VERSION ""

NS_ :

BS_:

BU_: EON XXX INTERCEPTOR ANY ACTUATOR SAFETY

CM_ "KommuActuator CAN messages starts here";

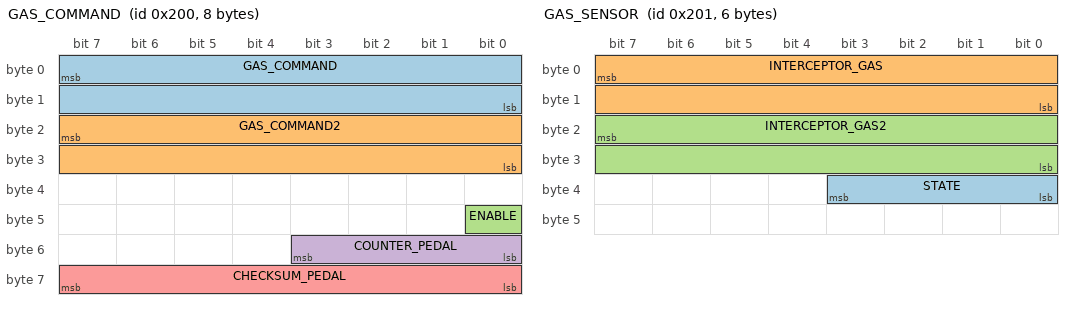
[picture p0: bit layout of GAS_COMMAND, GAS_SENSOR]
BO_ 512 GAS_COMMAND: 8 SAFETY
 SG_ GAS_COMMAND : 7|16@0+ (1,0) [0|1] "" ACTUATOR
 SG_ GAS_COMMAND2 : 23|16@0+ (1,0) [0|1] "" ACTUATOR
 SG_ ENABLE : 40|1@0+ (1,0) [0|1] "" ACTUATOR
 SG_ COUNTER_PEDAL : 51|4@0+ (1,0) [0|15] "" ACTUATOR
 SG_ CHECKSUM_PEDAL : 63|8@0+ (1,0) [0|255] "" ACTUATOR

BO_ 513 GAS_SENSOR: 6 ACTUATOR
 SG_ STATE : 35|4@0+ (1,0) [0|15] "" SAFETY
 SG_ INTERCEPTOR_GAS : 7|16@0+ (0.0007,-0.342) [0|1] "" SAFETY
 SG_ INTERCEPTOR_GAS2 : 23|16@0+ (0.0007,-0.691) [0|1] "" SAFETY

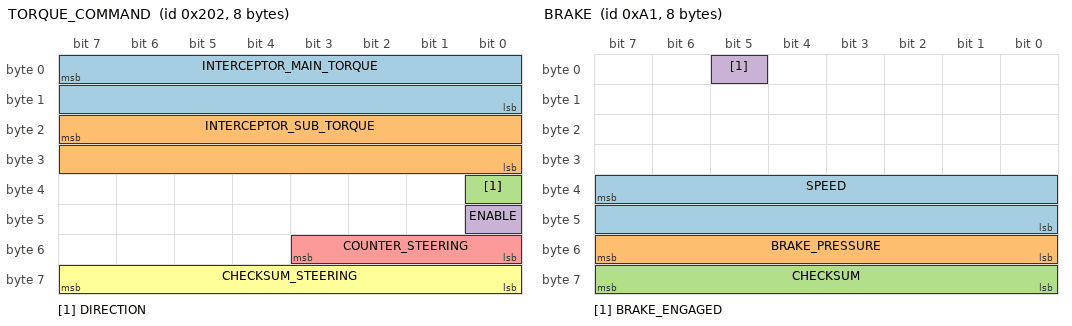
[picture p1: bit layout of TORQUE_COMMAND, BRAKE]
BO_ 514 TORQUE_COMMAND: 8 SAFETY
 SG_ INTERCEPTOR_MAIN_TORQUE : 7|16@0+ (1,0) [0|1] "" ACTUATOR
 SG_ INTERCEPTOR_SUB_TORQUE : 23|16@0+ (1,0) [0|1] "" ACTUATOR
 SG_ DIRECTION : 32|1@0+ (1,0) [0|1] "" ACTUATOR
 SG_ ENABLE : 40|1@0+ (1,0) [0|1] "" ACTUATOR
 SG_ COUNTER_STEERING : 51|4@0+ (1,0) [0|15] "" ACTUATOR
 SG_ CHECKSUM_STEERING : 63|8@0+ (1,0) [0|255] "" ACTUATOR

CM_ "Perodua Ativa CAN messages starts here";

BO_ 161 BRAKE: 8 XXX
 SG_ SPEED : 39|16@0+ (0.0108,0) [0|65535] "" XXX
 SG_ BRAKE_PRESSURE : 48|8@1+ (0.005532,0) [0|255] "" XXX
 SG_ CHECKSUM : 63|8@0+ (0.00003322,-0.00774026) [0|65535] "" XXX
 SG_ BRAKE_ENGAGED : 5|1@0+ (1,0) [0|1] "" XXX

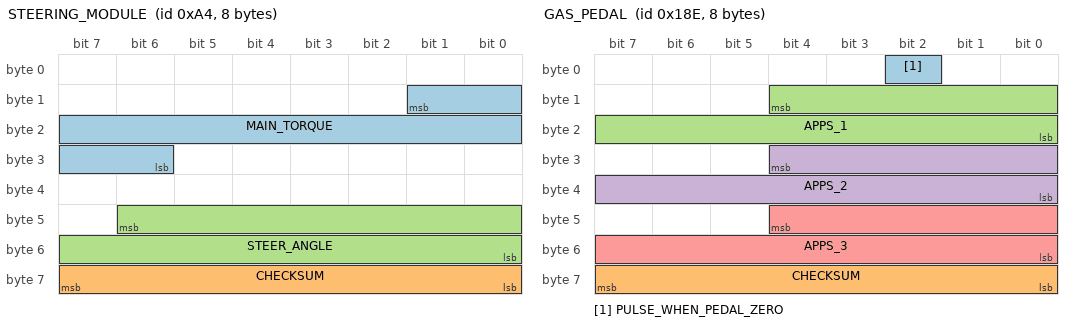
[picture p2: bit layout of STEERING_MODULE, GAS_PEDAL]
BO_ 164 STEERING_MODULE: 8 XXX
 SG_ MAIN_TORQUE : 9|12@0- (1,0) [0|65535] "" XXX
 SG_ CHECKSUM : 63|8@0+ (1,0) [0|255] "" XXX
 SG_ STEER_ANGLE : 46|15@0- (0.10047,0) [-500|500] "" XXX

BO_ 398 GAS_PEDAL: 8 XXX
 SG_ PULSE_WHEN_PEDAL_ZERO : 2|1@0+ (1,0) [0|1] "" XXX
 SG_ CHECKSUM : 63|8@0+ (1,0) [0|255] "" XXX
 SG_ APPS_1 : 12|13@0+ (0.00015625,0) [0|2097151] "%" XXX
 SG_ APPS_2 : 28|13@0+ (0.00006742,0) [0|1023] "" XXX
 SG_ APPS_3 : 44|13@0+ (0.00009,0) [0|7] "" XXX

BO_ 399 GAS_PEDAL_2: 8 XXX
 SG_ GAS_PEDAL_STEP : 1|1@0+ (1,0) [0|1] "" XXX
 SG_ IS_ACCEL : 5|1@0+ (1,0) [0|1] "" XXX

BO_ 410 AUTO_IDLE: 8 XXX
 SG_ AUTO_IDLE_EN : 8|1@1+ (1,0) [0|511] "" XXX
 SG_ AUTO_IDLE_BTN : 21|1@0+ (1,0) [0|1] "" XXX

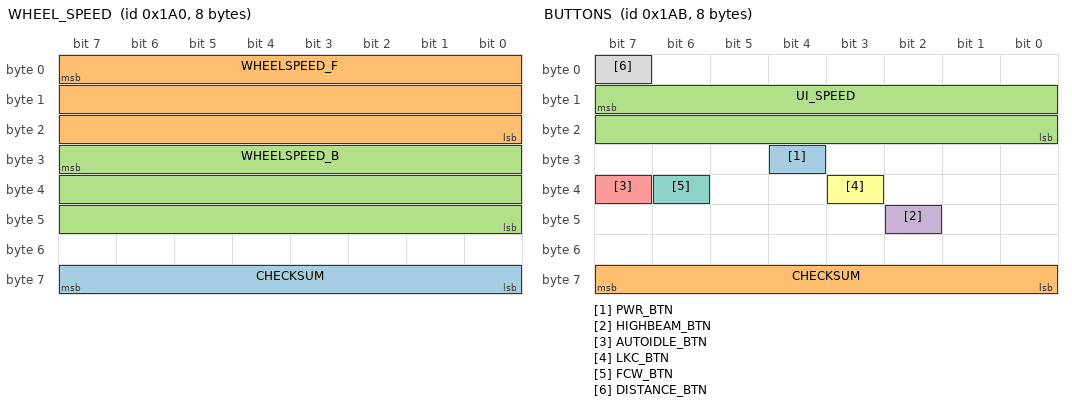
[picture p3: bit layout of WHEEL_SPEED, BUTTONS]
BO_ 416 WHEEL_SPEED: 8 XXX
 SG_ CHECKSUM : 63|8@0+ (1,0) [0|255] "" XXX
 SG_ WHEELSPEED_F : 7|24@0+ (0.00001,0) [0|16777215] "" XXX
 SG_ WHEELSPEED_B : 31|24@0+ (0.00000250,0) [0|16777215] "" XXX

BO_ 427 BUTTONS: 8 XXX
 SG_ PWR_BTN : 28|1@0+ (1,0) [0|1] "" XXX
 SG_ CHECKSUM : 63|8@0+ (1,0) [0|255] "" XXX
 SG_ UI_SPEED : 15|16@0+ (0.01,0) [0|65535] "" XXX
 SG_ HIGHBEAM_BTN : 42|1@0+ (1,0) [0|1] "" XXX
 SG_ AUTOIDLE_BTN : 39|1@0+ (1,0) [0|1] "" XXX
 SG_ LKC_BTN : 35|1@0+ (1,0) [0|1] "" XXX
 SG_ FCW_BTN : 38|1@1+ (1,0) [0|511] "" XXX
 SG_ DISTANCE_BTN : 7|1@0+ (1,0) [0|1] "" XXX

BO_ 448 EPS_SHAFT_TORQUE: 8 XXX
 SG_ CHECKSUM : 31|8@0+ (1,0) [0|255] "" XXX
 SG_ STEERING_TORQUE : 8|8@1+ (1,0) [0|255] "" XXX

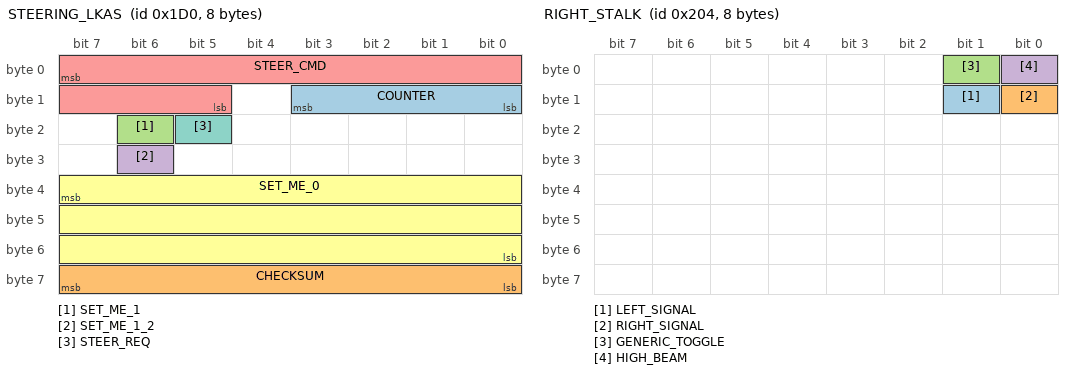
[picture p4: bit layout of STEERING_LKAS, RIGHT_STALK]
BO_ 464 STEERING_LKAS: 8 XXX
 SG_ COUNTER : 8|4@1+ (1,0) [0|15] "" XXX
 SG_ CHECKSUM : 63|8@0+ (1,0) [0|255] "" XXX
 SG_ SET_ME_1 : 22|1@0+ (1,0) [0|1] "" XXX
 SG_ SET_ME_1_2 : 30|1@0+ (1,0) [0|1] "" XXX
 SG_ STEER_CMD : 7|11@0- (1,0) [0|255] "" XXX
 SG_ SET_ME_0 : 39|24@0+ (1,0) [0|16777215] "" XXX
 SG_ STEER_REQ : 21|1@0+ (1,0) [0|1] "" XXX

BO_ 516 RIGHT_STALK: 8 XXX
 SG_ LEFT_SIGNAL : 9|1@0+ (1,0) [0|1] "" XXX
 SG_ RIGHT_SIGNAL : 8|1@0+ (1,0) [0|1] "" XXX
 SG_ GENERIC_TOGGLE : 1|1@0+ (1,0) [0|1] "" XXX
 SG_ HIGH_BEAM : 0|1@0+ (1,0) [0|1] "" XXX

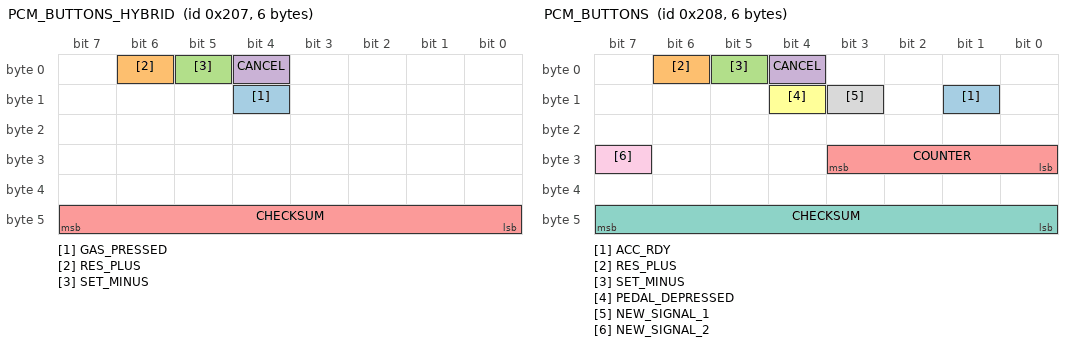
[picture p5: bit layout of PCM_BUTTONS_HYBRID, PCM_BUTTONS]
BO_ 519 PCM_BUTTONS_HYBRID: 6 XXX
 SG_ GAS_PRESSED : 12|1@0+ (1,0) [0|1] "" XXX
 SG_ RES_PLUS : 6|1@0+ (1,0) [0|1] "" XXX
 SG_ SET_MINUS : 5|1@0+ (1,0) [0|1] "" XXX
 SG_ CANCEL : 4|1@0+ (1,0) [0|1] "" XXX
 SG_ CHECKSUM : 40|8@1+ (1,0) [0|255] "" XXX

BO_ 520 PCM_BUTTONS: 6 XXX
 SG_ ACC_RDY : 9|1@0+ (1,0) [0|1] "" XXX
 SG_ RES_PLUS : 6|1@0+ (1,0) [0|1] "" XXX
 SG_ SET_MINUS : 5|1@0+ (1,0) [0|1] "" XXX
 SG_ CANCEL : 4|1@0+ (1,0) [0|1] "" XXX
 SG_ COUNTER : 24|4@1+ (1,0) [0|15] "" XXX
 SG_ PEDAL_DEPRESSED : 12|1@0+ (1,0) [0|1] "" XXX
 SG_ CHECKSUM : 40|8@1+ (1,0) [0|255] "" XXX
 SG_ NEW_SIGNAL_1 : 11|1@0+ (1,0) [0|1] "" XXX
 SG_ NEW_SIGNAL_2 : 31|1@0+ (1,0) [0|1] "" XXX

BO_ 524 TRANSMISSION: 8 XXX
 SG_ CHECKSUM : 47|8@0+ (1,0) [0|255] "" XXX
 SG_ GEAR : 15|4@0+ (1,0) [0|255] "" XXX

BO_ 608 WHEEL_SPEED_CLEAN: 8 XXX
 SG_ CHECKSUM : 63|8@0+ (1,0) [0|255] "" XXX
 SG_ WHEELSPEED : 44|13@0+ (0.011,0) [0|8191] "" XXX

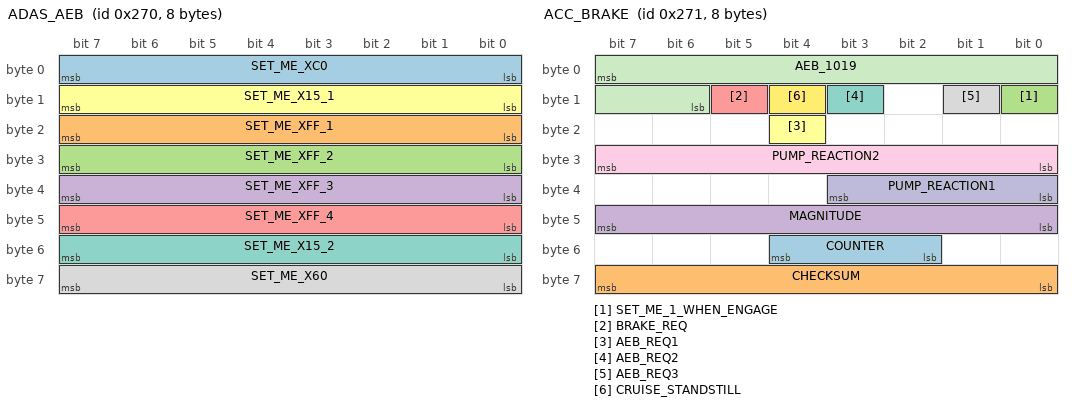
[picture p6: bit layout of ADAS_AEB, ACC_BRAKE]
BO_ 624 ADAS_AEB: 8 XXX
 SG_ SET_ME_XC0 : 7|8@0+ (1,0) [0|255] "" XXX
 SG_ SET_ME_XFF_1 : 23|8@0+ (1,0) [0|255] "" XXX
 SG_ SET_ME_XFF_2 : 31|8@0+ (1,0) [0|255] "" XXX
 SG_ SET_ME_XFF_3 : 39|8@0+ (1,0) [0|255] "" XXX
 SG_ SET_ME_XFF_4 : 47|8@0+ (1,0) [0|255] "" XXX
 SG_ SET_ME_X15_1 : 15|8@0+ (1,0) [0|255] "" XXX
 SG_ SET_ME_X15_2 : 55|8@0+ (1,0) [0|255] "" XXX
 SG_ SET_ME_X60 : 63|8@0+ (1,0) [0|255] "" XXX

BO_ 625 ACC_BRAKE: 8 XXX
 SG_ COUNTER : 52|3@0+ (1,0) [0|255] "" XXX
 SG_ CHECKSUM : 63|8@0+ (1,0) [0|255] "" XXX
 SG_ SET_ME_1_WHEN_ENGAGE : 8|1@0+ (1,0) [0|1] "" XXX
 SG_ MAGNITUDE : 47|8@0+ (0.01,-2) [0|255] "" XXX
 SG_ BRAKE_REQ : 13|1@0+ (1,0) [0|1] "" XXX
 SG_ AEB_REQ1 : 20|1@0+ (1,0) [0|1] "" XXX
 SG_ AEB_REQ2 : 11|1@0+ (1,0) [0|1] "" XXX
 SG_ AEB_REQ3 : 9|1@0+ (1,0) [0|1] "" XXX
 SG_ PUMP_REACTION2 : 31|8@0- (0.1,0) [0|16777215] "" XXX
 SG_ PUMP_REACTION1 : 35|4@0+ (0.1,0) [0|1] "" XXX
 SG_ AEB_1019 : 7|10@0+ (1,0) [0|255] "" XXX
 SG_ CRUISE_STANDSTILL : 12|1@0+ (1,0) [0|1] "" XXX

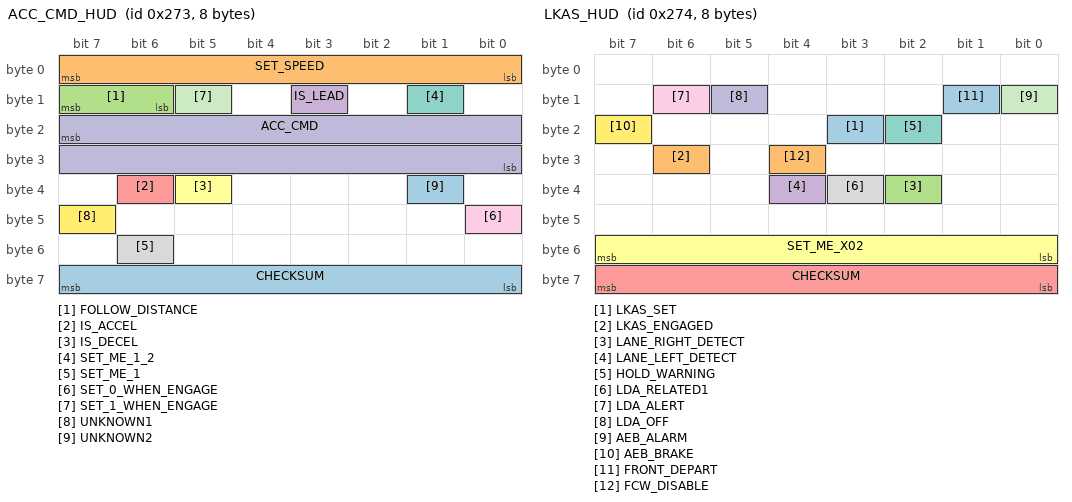
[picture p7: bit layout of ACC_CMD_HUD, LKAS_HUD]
BO_ 627 ACC_CMD_HUD: 8 XXX
 SG_ CHECKSUM : 63|8@0+ (1,0) [0|255] "" XXX
 SG_ SET_SPEED : 7|8@0+ (1,0) [0|255] "" XXX
 SG_ FOLLOW_DISTANCE : 15|2@0+ (1,0) [0|3] "" XXX
 SG_ IS_LEAD : 11|1@0+ (1,0) [0|1] "" XXX
 SG_ IS_ACCEL : 38|1@0+ (1,0) [0|1] "" XXX
 SG_ IS_DECEL : 37|1@0+ (1,0) [0|1] "" XXX
 SG_ SET_ME_1_2 : 9|1@0+ (1,0) [0|1] "" XXX
 SG_ SET_ME_1 : 54|1@0+ (1,0) [0|1] "" XXX
 SG_ SET_0_WHEN_ENGAGE : 40|1@0+ (1,0) [0|1] "" XXX
 SG_ ACC_CMD : 23|16@0+ (0.01,0) [0|127] "" XXX
 SG_ SET_1_WHEN_ENGAGE : 13|1@0+ (1,0) [0|1] "" XXX
 SG_ UNKNOWN1 : 47|1@0+ (1,0) [0|1] "" XXX
 SG_ UNKNOWN2 : 33|1@0+ (1,0) [0|1] "" XXX

VAL_ 627 FOLLOW_DISTANCE 2 "1bar" 1 "2bar" 0 "3bar" ;

BO_ 628 LKAS_HUD: 8 XXX
 SG_ LKAS_SET : 19|1@1+ (1,0) [0|3] "" XXX
 SG_ LKAS_ENGAGED : 30|1@0+ (1,0) [0|3] "" XXX
 SG_ LANE_RIGHT_DETECT : 34|1@0+ (1,0) [0|7] "" XXX
 SG_ LANE_LEFT_DETECT : 36|1@0+ (1,0) [0|1] "" XXX
 SG_ CHECKSUM : 63|8@0+ (1,0) [0|255] "" XXX
 SG_ SET_ME_X02 : 48|8@1+ (1,0) [0|3] "" XXX
 SG_ HOLD_WARNING : 18|1@0+ (1,0) [0|1] "" XXX
 SG_ LDA_RELATED1 : 35|1@0+ (1,0) [0|1] "" XXX
 SG_ LDA_ALERT : 14|1@0+ (1,0) [0|1] "" XXX
 SG_ LDA_OFF : 13|1@0+ (1,0) [0|1] "" XXX
 SG_ AEB_ALARM : 8|1@0+ (1,0) [0|1] "" XXX
 SG_ AEB_BRAKE : 23|1@0+ (1,0) [0|1] "" XXX
 SG_ FRONT_DEPART : 9|1@0+ (1,0) [0|1] "" XXX
 SG_ FCW_DISABLE : 28|1@0+ (1,0) [0|1] "" XXX

BO_ 834 BSM: 8 XXX
 SG_ BSM_CHIME : 23|1@0+ (1,0) [0|1] "" XXX

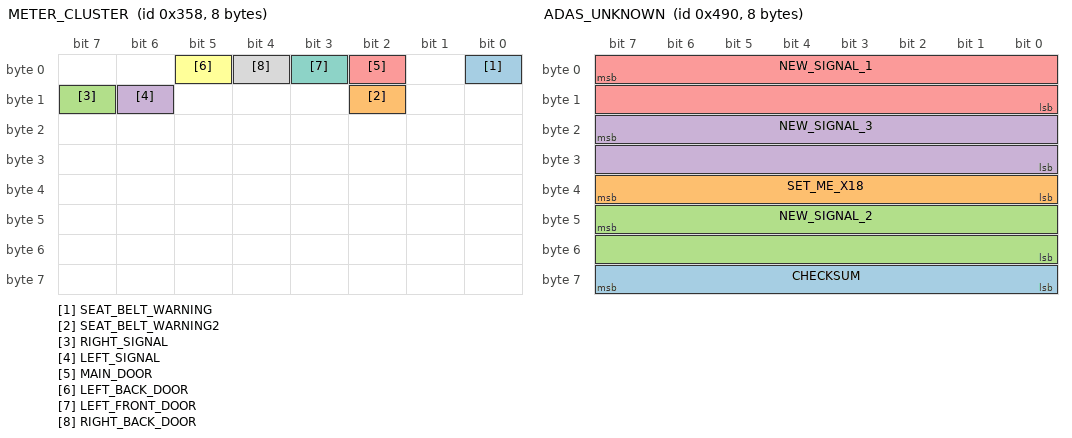
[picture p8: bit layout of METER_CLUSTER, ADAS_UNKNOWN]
BO_ 856 METER_CLUSTER: 8 XXX
 SG_ SEAT_BELT_WARNING : 0|1@0+ (1,0) [0|1] "" XXX
 SG_ SEAT_BELT_WARNING2 : 10|1@0+ (1,0) [0|1] "" XXX
 SG_ RIGHT_SIGNAL : 15|1@0+ (1,0) [0|3] "" XXX
 SG_ LEFT_SIGNAL : 14|1@0+ (1,0) [0|3] "" XXX
 SG_ MAIN_DOOR : 2|1@1+ (1,0) [0|3] "" XXX
 SG_ LEFT_BACK_DOOR : 5|1@0+ (1,0) [0|1] "" XXX
 SG_ LEFT_FRONT_DOOR : 3|1@0+ (1,0) [0|1] "" XXX
 SG_ RIGHT_BACK_DOOR : 4|1@0+ (1,0) [0|1] "" XXX

BO_ 900 HANDBRAKE: 8 XXX
 SG_ HANDBRAKE_ENGAGED : 24|1@0+ (1,0) [0|1] "" XXX

BO_ 1168 ADAS_UNKNOWN: 8 XXX
 SG_ CHECKSUM : 63|8@0+ (1,0) [0|255] "" XXX
 SG_ SET_ME_X18 : 39|8@0+ (1,0) [0|255] "" XXX
 SG_ NEW_SIGNAL_2 : 47|16@0- (1,0) [0|65535] "" XXX
 SG_ NEW_SIGNAL_3 : 23|16@0- (1,0) [0|65535] "" XXX
 SG_ NEW_SIGNAL_1 : 7|16@0- (1,0) [0|4294967295] "" XXX

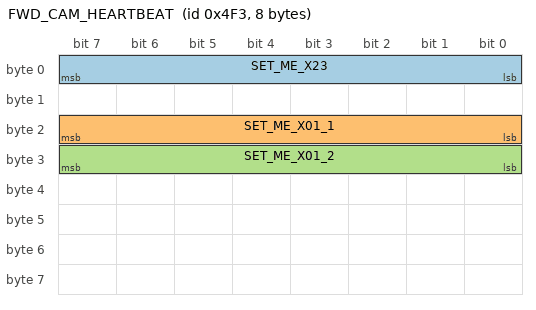
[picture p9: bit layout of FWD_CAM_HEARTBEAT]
BO_ 1267 FWD_CAM_HEARTBEAT: 8 CAR
 SG_ SET_ME_X23 : 7|8@0+ (1,0) [0|255] "" ANY
 SG_ SET_ME_X01_1 : 23|8@0+ (1,0) [0|255] "" ANY
 SG_ SET_ME_X01_2 : 31|8@0+ (1,0) [0|255] "" ANY

BO_ 8 STAYALIVE_1: 0 XXX

BO_ 51 STAYALIVE_2: 0 XXX

VAL_ 513 STATE 5 "FAULT_TIMEOUT" 4 "FAULT_STARTUP" 3 "FAULT_SCE" 2 "FAULT_SEND" 1 "FAULT_BAD_CHECKSUM" 0 "NO_FAULT" ;
VAL_ 524 GEAR 8 "R" 4 "N" 2 "D" 0 "P" ;
